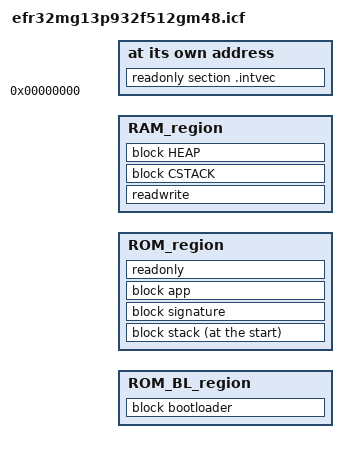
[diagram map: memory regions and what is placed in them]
/*###ICF### Section handled by ICF editor, don't touch! ****/
/*-Editor annotation file-*/
/* IcfEditorFile="$TOOLKIT_DIR$\config\ide\IcfEditor\cortex_v1_0.xml" */

/*-Specials-*/
define symbol __ICFEDIT_intvec_start__ = 0x00000000;

/*-Memory Regions-*/
define symbol __ICFEDIT_region_ROM_BL_start__   = 0x0FE10000;
define symbol __ICFEDIT_region_ROM_BL_end__     = (0x0FE10000+0x4000-1);
define symbol __ICFEDIT_region_ROM_start__   = 0x0000;
define symbol __ICFEDIT_region_ROM_end__     = (0x00080000-2048*2-1);
define symbol __ICFEDIT_region_RAM_start__   = 0x20000000;
define symbol __ICFEDIT_region_RAM_end__     = (0x20000000+0x00010000-1-4);

/*-Sizes-*/
define symbol __ICFEDIT_size_cstack__      = 0x800;
define symbol __ICFEDIT_size_heap__        = 0x800;
define symbol __ICFEDIT_size_signature__   = 0x40;
/**** End of ICF editor section. ###ICF###*/


/*12KiB ram for stack*/
define symbol blob_ram_size    = 0x3000;


define memory mem with size = 4G;
define region ROM_BL_region   = mem:[from __ICFEDIT_region_ROM_BL_start__ to __ICFEDIT_region_ROM_BL_end__];
define region ROM_region   = mem:[from __ICFEDIT_region_ROM_start__ to __ICFEDIT_region_ROM_end__];
define region RAM_region   = mem:[from __ICFEDIT_region_RAM_start__+blob_ram_size to __ICFEDIT_region_RAM_end__];

define block CSTACK    with alignment = 8, size = __ICFEDIT_size_cstack__   { };
define block HEAP      with alignment = 8, size = __ICFEDIT_size_heap__     { };

initialize by copy { readwrite };
do not initialize  { section .noinit };

if (!isdefinedsymbol(static_link))
{
define block stack with alignment = 2048
{
  readonly section .binstack
};
define block bootloader with size=0x4000
{
  readonly section .binbootloader,
};
define block signature with size = __ICFEDIT_size_signature__
{
};


define block app with fixed order, alignment = 2048
{
  readonly section .AAT,
  readonly section .intvec,  
  readonly 
};

keep { section .intvec };
keep { section .AAT };
keep { section .binbootloader };
keep { section .binstack };
keep { block signature };

".text_bootloader":
place in ROM_BL_region  { block bootloader };

".text_stack":
place at start of ROM_region  { block stack };

".text_signature":
place in ROM_region  { block signature };

".text_app":
place in ROM_region   { block app };


}else
{	
keep { section .intvec };
place at address mem:__ICFEDIT_intvec_start__ { readonly section .intvec };
place in ROM_region   { readonly };
}
place in RAM_region   { readwrite,
                        block CSTACK, 
                        block HEAP };
                        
